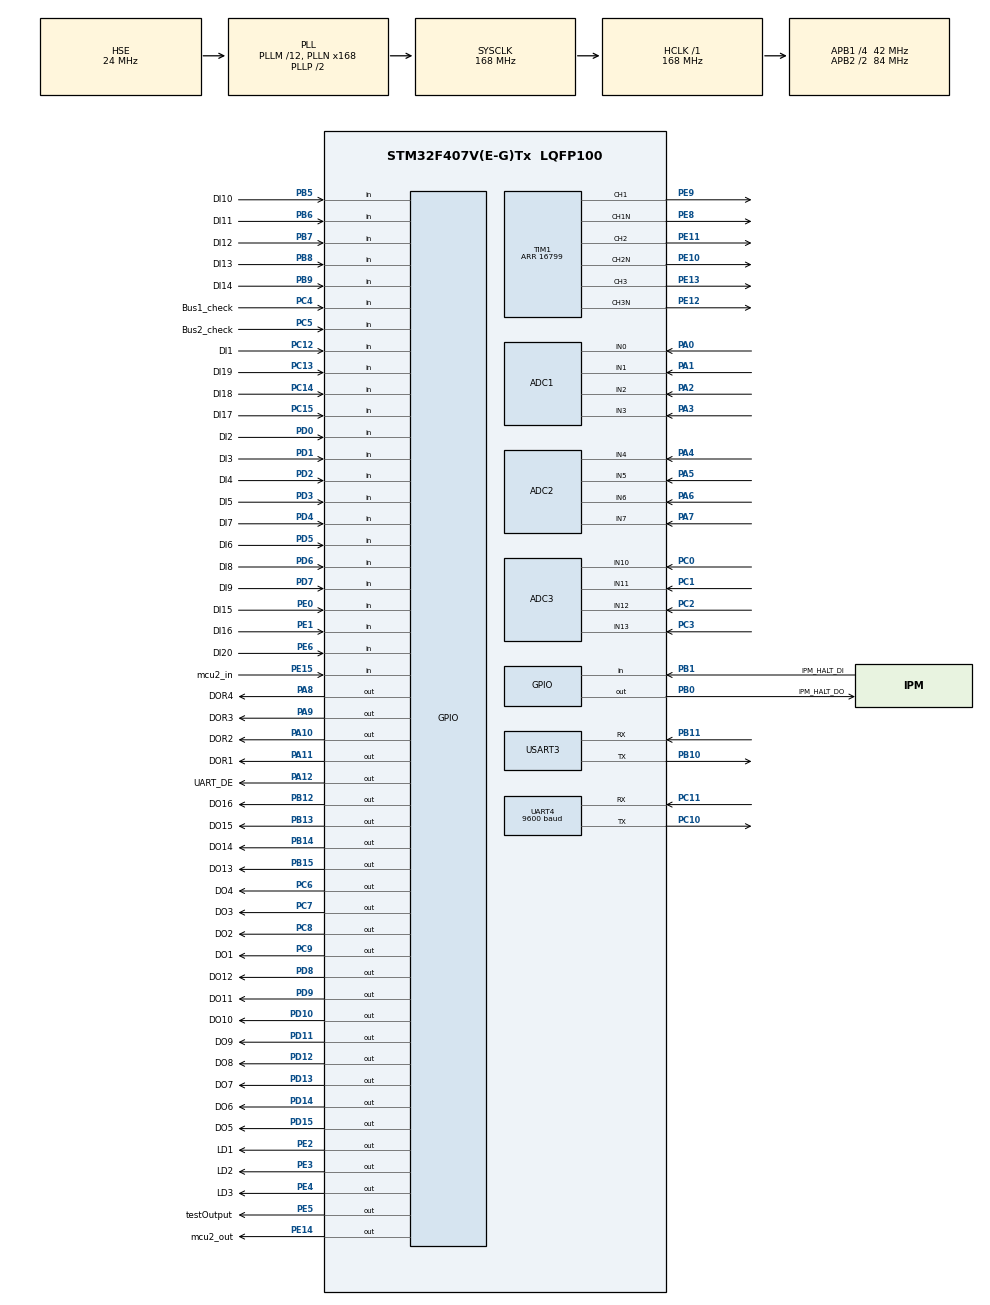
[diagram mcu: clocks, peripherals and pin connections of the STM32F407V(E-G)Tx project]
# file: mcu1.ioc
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ADC1.Channel-0\#ChannelRegularConversion=ADC_CHANNEL_1
ADC1.Channel-3\#ChannelRegularConversion=ADC_CHANNEL_0
ADC1.Channel-4\#ChannelRegularConversion=ADC_CHANNEL_2
ADC1.DMAAccessMode=ADC_DMAACCESSMODE_1
ADC1.DMAContinuousRequests=ENABLE
ADC1.EOCSelection=ADC_EOC_SEQ_CONV
ADC1.ExternalTrigConv=ADC_EXTERNALTRIGCONV_T2_TRGO
ADC1.Mode=ADC_TRIPLEMODE_REGSIMULT
ADC1.NbrOfConversion=3
ADC1.NbrOfConversionFlag=1
ADC1.Rank-3\#ChannelRegularConversion=2
ADC1.Rank-4\#ChannelRegularConversion=3
ADC1.SamplingTime-0\#ChannelRegularConversion=ADC_SAMPLETIME_15CYCLES
ADC1.SamplingTime-3\#ChannelRegularConversion=ADC_SAMPLETIME_15CYCLES
ADC1.SamplingTime-4\#ChannelRegularConversion=ADC_SAMPLETIME_15CYCLES
ADC1.ScanConvMode=ENABLE
ADC1.master=1
ADC2.Channel-1\#ChannelRegularConversion=ADC_CHANNEL_5
ADC2.Channel-4\#ChannelRegularConversion=ADC_CHANNEL_4
ADC2.Channel-5\#ChannelRegularConversion=ADC_CHANNEL_6
ADC2.DMAAccessMode=ADC_DMAACCESSMODE_1
ADC2.EOCSelection=ADC_EOC_SEQ_CONV
ADC2.InjNumberOfConversion=0
ADC2.Mode=ADC_TRIPLEMODE_REGSIMULT
ADC2.NbrOfConversion=3
ADC2.NbrOfConversionFlag=1
ADC2.Rank-4\#ChannelRegularConversion=2
ADC2.Rank-5\#ChannelRegularConversion=3
ADC2.SamplingTime-1\#ChannelRegularConversion=ADC_SAMPLETIME_15CYCLES
ADC2.SamplingTime-4\#ChannelRegularConversion=ADC_SAMPLETIME_15CYCLES
ADC2.SamplingTime-5\#ChannelRegularConversion=ADC_SAMPLETIME_15CYCLES
ADC3.Channel-0\#ChannelRegularConversion=ADC_CHANNEL_11
ADC3.Channel-3\#ChannelRegularConversion=ADC_CHANNEL_10
ADC3.Channel-4\#ChannelRegularConversion=ADC_CHANNEL_12
ADC3.DMAAccessMode=ADC_DMAACCESSMODE_1
ADC3.InjNumberOfConversion=0
ADC3.Mode=ADC_TRIPLEMODE_REGSIMULT
ADC3.NbrOfConversion=3
ADC3.NbrOfConversionFlag=1
ADC3.Rank-3\#ChannelRegularConversion=2
ADC3.Rank-4\#ChannelRegularConversion=3
ADC3.SamplingTime-0\#ChannelRegularConversion=ADC_SAMPLETIME_15CYCLES
ADC3.SamplingTime-3\#ChannelRegularConversion=ADC_SAMPLETIME_15CYCLES
ADC3.SamplingTime-4\#ChannelRegularConversion=ADC_SAMPLETIME_15CYCLES
ADC3.ScanConvMode=ENABLE
Dma.ADC1.0.Direction=DMA_PERIPH_TO_MEMORY
Dma.ADC1.0.FIFOMode=DMA_FIFOMODE_DISABLE
Dma.ADC1.0.Instance=DMA2_Stream0
Dma.ADC1.0.MemDataAlignment=DMA_MDATAALIGN_WORD
Dma.ADC1.0.MemInc=DMA_MINC_ENABLE
Dma.ADC1.0.Mode=DMA_CIRCULAR
Dma.ADC1.0.PeriphDataAlignment=DMA_PDATAALIGN_WORD
Dma.ADC1.0.PeriphInc=DMA_PINC_DISABLE
Dma.ADC1.0.Priority=DMA_PRIORITY_HIGH
Dma.Request0=ADC1
Mcu.Family=STM32F4
Mcu.Name=STM32F407V(E-G)Tx
Mcu.Package=LQFP100
NVIC.DMA2_Stream0_IRQn=true\:0\:0\:false\:false\:true\:false\:true
NVIC.PriorityGroup=NVIC_PRIORITYGROUP_4
NVIC.TIM2_IRQn=true\:0\:0\:false\:false\:true\:true\:true
NVIC.UART4_IRQn=true\:0\:0\:false\:false\:true\:true\:true
PA0-WKUP.Signal=ADCx_IN0
PA1.Signal=ADCx_IN1
PA10.GPIO_Label=DOR2
PA10.Signal=GPIO_Output
PA11.GPIO_Label=DOR1
PA11.Signal=GPIO_Output
PA12.GPIO_Label=UART_DE
PA12.Signal=GPIO_Output
PA13.Mode=JTAG_5_pins
PA13.Signal=SYS_JTMS-SWDIO
PA14.Mode=JTAG_5_pins
PA14.Signal=SYS_JTCK-SWCLK
PA15.Mode=JTAG_5_pins
PA15.Signal=SYS_JTDI
PA2.Signal=ADCx_IN2
PA3.Signal=ADCx_IN3
PA4.Signal=ADCx_IN4
PA5.Signal=ADCx_IN5
PA6.Signal=ADCx_IN6
PA7.Signal=ADCx_IN7
PA8.GPIO_Label=DOR4
PA8.Signal=GPIO_Output
PA9.GPIO_Label=DOR3
PA9.Signal=GPIO_Output
PB0.GPIO_Label=IPM_HALT_DO
PB0.Signal=GPIO_Output
PB1.GPIO_Label=IPM_HALT_DI
PB1.Signal=GPIO_Input
PB10.Mode=Asynchronous
PB10.Signal=USART3_TX
PB11.Mode=Asynchronous
PB11.Signal=USART3_RX
PB12.GPIO_Label=DO16
PB12.Signal=GPIO_Output
PB13.GPIO_Label=DO15
PB13.Signal=GPIO_Output
PB14.GPIO_Label=DO14
PB14.Signal=GPIO_Output
PB15.GPIO_Label=DO13
PB15.Signal=GPIO_Output
PB3.Mode=JTAG_5_pins
PB3.Signal=SYS_JTDO-SWO
PB4.Mode=JTAG_5_pins
PB4.Signal=SYS_JTRST
PB5.GPIO_Label=DI10
PB5.Signal=GPIO_Input
PB6.GPIO_Label=DI11
PB6.Signal=GPIO_Input
PB7.GPIO_Label=DI12
PB7.Signal=GPIO_Input
PB8.GPIO_Label=DI13
PB8.Signal=GPIO_Input
PB9.GPIO_Label=DI14
PB9.Signal=GPIO_Input
PC0.Signal=ADCx_IN10
PC1.Signal=ADCx_IN11
PC10.GPIO_Speed=GPIO_SPEED_FREQ_HIGH
PC10.Mode=Asynchronous
PC10.Signal=UART4_TX
PC11.GPIO_PuPd=GPIO_PULLUP
PC11.GPIO_Speed=GPIO_SPEED_FREQ_HIGH
PC11.Mode=Asynchronous
PC11.Signal=UART4_RX
PC12.GPIO_Label=DI1
PC12.Signal=GPIO_Input
PC13-ANTI_TAMP.GPIO_Label=DI19
PC13-ANTI_TAMP.Signal=GPIO_Input
PC14-OSC32_IN.GPIO_Label=DI18
PC14-OSC32_IN.Signal=GPIO_Input
PC15-OSC32_OUT.GPIO_Label=DI17
PC15-OSC32_OUT.Signal=GPIO_Input
PC2.Signal=ADCx_IN12
PC3.Signal=ADCx_IN13
PC4.GPIO_Label=Bus1_check
PC4.Signal=GPIO_Input
PC5.GPIO_Label=Bus2_check
PC5.Signal=GPIO_Input
PC6.GPIO_Label=DO4
PC6.Signal=GPIO_Output
PC7.GPIO_Label=DO3
PC7.Signal=GPIO_Output
PC8.GPIO_Label=DO2
PC8.Signal=GPIO_Output
PC9.GPIO_Label=DO1
PC9.Signal=GPIO_Output
PD0.GPIO_Label=DI2
PD0.Signal=GPIO_Input
PD1.GPIO_Label=DI3
PD1.Signal=GPIO_Input
PD10.GPIO_Label=DO10
PD10.Signal=GPIO_Output
PD11.GPIO_Label=DO9
PD11.Signal=GPIO_Output
PD12.GPIO_Label=DO8
PD12.Signal=GPIO_Output
PD13.GPIO_Label=DO7
PD13.Signal=GPIO_Output
PD14.GPIO_Label=DO6
PD14.Signal=GPIO_Output
PD15.GPIO_Label=DO5
PD15.Signal=GPIO_Output
PD2.GPIO_Label=DI4
PD2.Signal=GPIO_Input
PD3.GPIO_Label=DI5
PD3.Signal=GPIO_Input
PD4.GPIO_Label=DI7
PD4.Signal=GPIO_Input
PD5.GPIO_Label=DI6
PD5.Signal=GPIO_Input
PD6.GPIO_Label=DI8
PD6.Signal=GPIO_Input
PD7.GPIO_Label=DI9
PD7.Signal=GPIO_Input
PD8.GPIO_Label=DO12
PD8.Signal=GPIO_Output
PD9.GPIO_Label=DO11
PD9.Signal=GPIO_Output
PE0.GPIO_Label=DI15
PE0.Signal=GPIO_Input
PE1.GPIO_Label=DI16
PE1.Signal=GPIO_Input
PE10.Mode=PWM Generation2 CH2 CH2N
PE10.Signal=TIM1_CH2N
PE11.Signal=S_TIM1_CH2
PE12.Mode=PWM Generation3 CH3 CH3N
PE12.Signal=TIM1_CH3N
PE13.Signal=S_TIM1_CH3
PE14.GPIO_Label=mcu2_out
PE14.Signal=GPIO_Output
PE15.GPIO_Label=mcu2_in
PE15.Signal=GPIO_Input
PE2.GPIO_Label=LD1
PE2.Signal=GPIO_Output
PE3.GPIO_Label=LD2
PE3.Signal=GPIO_Output
PE4.GPIO_Label=LD3
PE4.Signal=GPIO_Output
PE5.GPIO_Label=testOutput
PE5.Signal=GPIO_Output
PE6.GPIO_Label=DI20
PE6.Signal=GPIO_Input
PE8.Mode=PWM Generation1 CH1 CH1N
PE8.Signal=TIM1_CH1N
PE9.Signal=S_TIM1_CH1
PH0-OSC_IN.Mode=HSE-External-Oscillator
PH0-OSC_IN.Signal=RCC_OSC_IN
PH1-OSC_OUT.Mode=HSE-External-Oscillator
PH1-OSC_OUT.Signal=RCC_OSC_OUT
ProjectManager.HeapSize=0x200
ProjectManager.StackSize=0x400
ProjectManager.TargetToolchain=MDK-ARM V5.32
RCC.48MHZClocksFreq_Value=84000000
RCC.AHBFreq_Value=168000000
RCC.APB1CLKDivider=RCC_HCLK_DIV4
RCC.APB1Freq_Value=42000000
RCC.APB1TimFreq_Value=84000000
RCC.APB2CLKDivider=RCC_HCLK_DIV2
RCC.APB2Freq_Value=84000000
RCC.APB2TimFreq_Value=168000000
RCC.CortexFreq_Value=168000000
RCC.HCLKFreq_Value=168000000
RCC.HSE_VALUE=24000000
RCC.HSI_VALUE=16000000
RCC.LSE_VALUE=32768
RCC.PLLM=12
RCC.PLLN=168
RCC.PLLSourceVirtual=RCC_PLLSOURCE_HSE
RCC.SYSCLKFreq_VALUE=168000000
RCC.SYSCLKSource=RCC_SYSCLKSOURCE_PLLCLK
RCC.VCOOutputFreq_Value=336000000
SH.ADCx_IN0.0=ADC1_IN0,IN0
SH.ADCx_IN1.0=ADC1_IN1,IN1
SH.ADCx_IN10.0=ADC3_IN10,IN10
SH.ADCx_IN11.0=ADC3_IN11,IN11
SH.ADCx_IN12.0=ADC3_IN12,IN12
SH.ADCx_IN13.0=ADC3_IN13,IN13
SH.ADCx_IN2.0=ADC1_IN2,IN2
SH.ADCx_IN3.0=ADC1_IN3,IN3
SH.ADCx_IN4.0=ADC2_IN4,IN4
SH.ADCx_IN5.0=ADC2_IN5,IN5
SH.ADCx_IN6.0=ADC2_IN6,IN6
SH.ADCx_IN7.0=ADC2_IN7,IN7
SH.S_TIM1_CH1.0=TIM1_CH1,PWM Generation1 CH1 CH1N
SH.S_TIM1_CH2.0=TIM1_CH2,PWM Generation2 CH2 CH2N
SH.S_TIM1_CH3.0=TIM1_CH3,PWM Generation3 CH3 CH3N
TIM1.AutoReloadPreload=TIM_AUTORELOAD_PRELOAD_ENABLE
TIM1.Channel-PWM\ Generation1\ CH1\ CH1N=TIM_CHANNEL_1
TIM1.Channel-PWM\ Generation2\ CH2\ CH2N=TIM_CHANNEL_2
TIM1.Channel-PWM\ Generation3\ CH3\ CH3N=TIM_CHANNEL_3
TIM1.CounterMode=TIM_COUNTERMODE_CENTERALIGNED1
TIM1.Period=16799
TIM2.Period=8399
TIM2.TIM_MasterOutputTrigger=TIM_TRGO_UPDATE
UART4.BaudRate=9600
UART4.VirtualMode=Asynchronous
USART3.VirtualMode=VM_ASYNC
VP_TIM2_VS_ClockSourceINT.Mode=Internal
board=custom

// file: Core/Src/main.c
/* USER CODE BEGIN Header */
/**
  ******************************************************************************
  * @file           : main.c
  * @brief          : Main program body
  ******************************************************************************
  * @attention
  *
  * Copyright (c) 2022 STMicroelectronics.
  * All rights reserved.
  *
  * This software is licensed under terms that can be found in the LICENSE file
  * in the root directory of this software component.
  * If no LICENSE file comes with this software, it is provided AS-IS.
  *
  ******************************************************************************
  */
/* USER CODE END Header */
#include "main.h"
#include "adc.h"
#include "dma.h"
#include "tim.h"
#include "usart.h"
#include "gpio.h"

/* USER CODE BEGIN Includes */
#include "functionPrototypes.h"
#include "adcHandling.h"
/* USER CODE END Includes */

/* USER CODE BEGIN PV */

uint8_t mainCount=0;

/* USER CODE END PV */

void SystemClock_Config(void);

int main(void)
{

  /* MCU Configuration--------------------------------------------------------*/

  /* Reset of all peripherals, Initializes the Flash interface and the Systick. */
   HAL_Init();

  /* Configure the system clock */
  SystemClock_Config();

  /* USER CODE BEGIN SysInit */
	MX_DMA_Init();
  /* USER CODE END SysInit */

  /* Initialize all configured peripherals */
  MX_GPIO_Init();
  MX_ADC1_Init();
  MX_ADC2_Init();
  MX_ADC3_Init();
  MX_TIM1_Init();
  MX_UART4_Init();
  MX_DMA_Init();
  MX_USART3_UART_Init();
  MX_TIM2_Init();

  /* Infinite loop */
  /* USER CODE BEGIN WHILE */
	initialization();

  while (1)
  {
    /* USER CODE END WHILE */

    /* USER CODE BEGIN 3 */
		if(adc_completed==1){

		LEDs();
		mainLoopCommPart();

		}

  }
  /* USER CODE END 3 */
}

void SystemClock_Config(void)
{
  RCC_OscInitTypeDef RCC_OscInitStruct = {0};
  RCC_ClkInitTypeDef RCC_ClkInitStruct = {0};

  /** Configure the main internal regulator output voltage
  */
  __HAL_RCC_PWR_CLK_ENABLE();
  __HAL_PWR_VOLTAGESCALING_CONFIG(PWR_REGULATOR_VOLTAGE_SCALE1);
  /** Initializes the RCC Oscillators according to the specified parameters
  * in the RCC_OscInitTypeDef structure.
  */
  RCC_OscInitStruct.OscillatorType = RCC_OSCILLATORTYPE_HSE;
  RCC_OscInitStruct.HSEState = RCC_HSE_ON;
  RCC_OscInitStruct.PLL.PLLState = RCC_PLL_ON;
  RCC_OscInitStruct.PLL.PLLSource = RCC_PLLSOURCE_HSE;
  RCC_OscInitStruct.PLL.PLLM = 12;
  RCC_OscInitStruct.PLL.PLLN = 168;
  RCC_OscInitStruct.PLL.PLLP = RCC_PLLP_DIV2;
  RCC_OscInitStruct.PLL.PLLQ = 4;
  if (HAL_RCC_OscConfig(&RCC_OscInitStruct) != HAL_OK)
  {
    Error_Handler();
  }
  /** Initializes the CPU, AHB and APB buses clocks
  */
  RCC_ClkInitStruct.ClockType = RCC_CLOCKTYPE_HCLK|RCC_CLOCKTYPE_SYSCLK
                              |RCC_CLOCKTYPE_PCLK1|RCC_CLOCKTYPE_PCLK2;
  RCC_ClkInitStruct.SYSCLKSource = RCC_SYSCLKSOURCE_PLLCLK;
  RCC_ClkInitStruct.AHBCLKDivider = RCC_SYSCLK_DIV1;
  RCC_ClkInitStruct.APB1CLKDivider = RCC_HCLK_DIV4;
  RCC_ClkInitStruct.APB2CLKDivider = RCC_HCLK_DIV2;

  if (HAL_RCC_ClockConfig(&RCC_ClkInitStruct, FLASH_LATENCY_5) != HAL_OK)
  {
    Error_Handler();
  }
}

void Error_Handler(void)
{
  __disable_irq();
  while (1)
  {
  }
}
